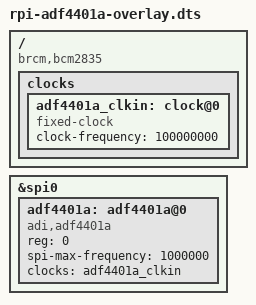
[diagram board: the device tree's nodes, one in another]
/dts-v1/;
/plugin/;
/ {
    compatible = "brcm,bcm2835";
    fragment@0 {
        target-path = "/";
        __overlay__ {
            clocks {
                adf4401a_clkin: clock@0 {
                         #clock-cells = <0>;
                         compatible = "fixed-clock";
                         clock-frequency = <100000000>; // 100MHz
                };
            };
        };
    };
    fragment@1 {
        target = <&spi0>;
        __overlay__ {
            #address-cells = <1>;
            #size-cells = <0>;
            status = "okay";
            adf4401a: adf4401a@0 {
                compatible = "adi,adf4401a";
                reg = <0>;
                spi-max-frequency = <1000000>;
                clocks = <&adf4401a_clkin>;
                clock-names = "clkin";
            };
        };
    };
    
};
